# STM32G534 register map
File version: 2.0.0
CPU: CM33 r0p4, little endian, MPU, FPU, 4 interrupt priority bits
Registers are 32-bit, read-write, reset 0x0 unless marked. A register's access mark holds for its fields unless they carry their own. Offsets are from the block's base; [hi:lo] are bit positions; {n}, {i} and the like mark numbered series.

## FMAC1 — FMAC register block
Base 0x40023C00
Same registers: FMAC1_S 0x50023C00
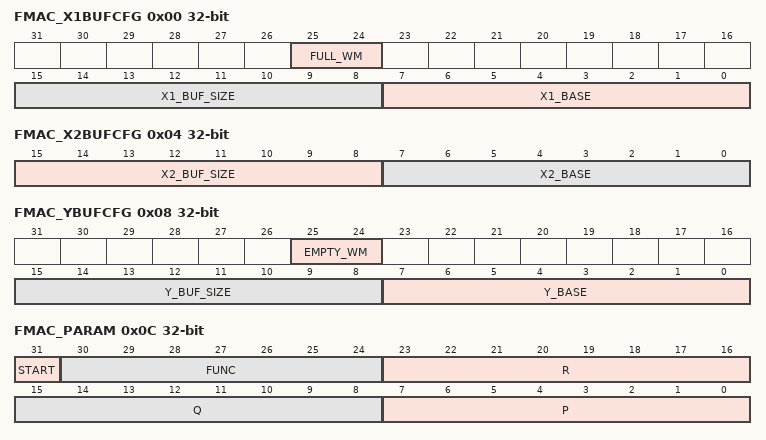
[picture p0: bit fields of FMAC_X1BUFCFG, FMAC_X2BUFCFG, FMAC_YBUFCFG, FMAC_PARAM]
0x00 FMAC_X1BUFCFG — FMAC X1 buffer configuration register
  [25:24] FULL_WM — Watermark for buffer full flag
    0=Threshold = 1; 1=Threshold = 2
  [15:8] X1_BUF_SIZE — Allocated size of X1 buffer in 16-bit words
  [7:0] X1_BASE — Base address of X1 buffer
0x04 FMAC_X2BUFCFG — FMAC X2 buffer configuration register
  [15:8] X2_BUF_SIZE — Size of X2 buffer in 16-bit words
  [7:0] X2_BASE — Base address of X2 buffer
0x08 FMAC_YBUFCFG — FMAC Y buffer configuration register
  [25:24] EMPTY_WM — Watermark for buffer empty flag
    0=Threshold = 1; 1=Threshold = 2
  [15:8] Y_BUF_SIZE — Size of Y buffer in 16-bit words
  [7:0] Y_BASE — Base address of Y buffer
0x0C FMAC_PARAM — FMAC parameter register
  [31] START — Enable execution
    0=Stop execution; 1=Start execution
  [30:24] FUNC — Function
    1=Load X1 buffer
  [23:16] R — Input parameter R.
  [15:8] Q — Input parameter Q.
  [7:0] P — Input parameter P.
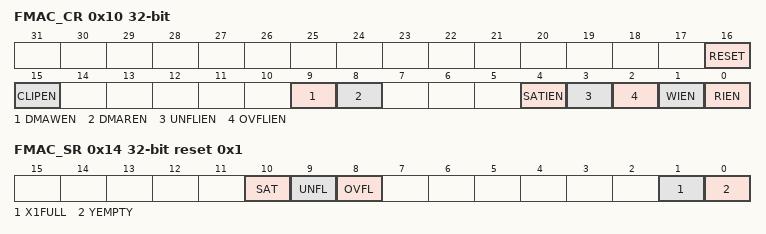
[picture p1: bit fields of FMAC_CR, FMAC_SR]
0x10 FMAC_CR — FMAC control register
  [16] RESET — Reset FMAC unit
    0=Reset inactive; 1=Reset active
  [15] CLIPEN — Enable clipping
    0=Clipping disabled; 1=Clipping enabled
  [9] DMAWEN — Enable DMA write channel requests
    0=Disable; 1=Enable
  [8] DMAREN — Enable DMA read channel requests
    0=Disable; 1=Enable
  [4] SATIEN — Enable saturation error interrupts
    0=Disabled; 1=Enabled
  [3] UNFLIEN — Enable underflow error interrupts
    0=Disabled; 1=Enabled
  [2] OVFLIEN — Enable overflow error interrupts
    0=Disabled; 1=Enabled
  [1] WIEN — Enable write interrupt
    0=Disabled; 1=Enabled
  [0] RIEN — Enable read interrupt
    0=Disabled; 1=Enabled
0x14 FMAC_SR ro reset 0x1 — FMAC status register
  [10] SAT — Saturation error flag
    0=No saturation detected; 1=Saturation detected
  [9] UNFL — Underflow error flag
    0=No underflow detected; 1=Underflow detected
  [8] OVFL — Overflow error flag
    0=No overflow detected; 1=Overflow detected
  [1] X1FULL — X1 buffer full flag
    0=X1 buffer not full; 1=X1 buffer full
  [0] YEMPTY — Y buffer empty flag
    0=Y buffer not empty; 1=Y buffer empty
0x18 FMAC_WDATA wo — FMAC write data register
  [15:0] WDATA — Write data
0x1C FMAC_RDATA ro — FMAC read data register
  [15:0] RDATA — Read data

## GTZC1_MPCBB2 — GTZC1_MPCBB2 register block
Base 0x40033000
Same registers: GTZC1_MPCBB2_S 0x50033000
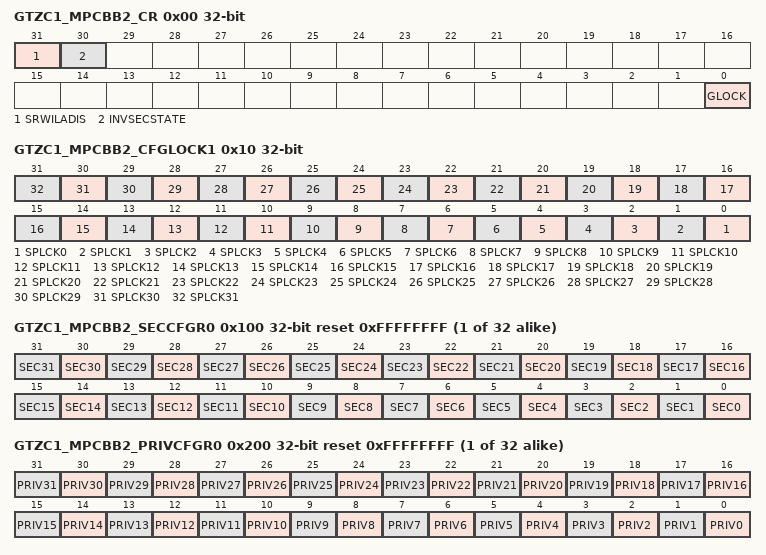
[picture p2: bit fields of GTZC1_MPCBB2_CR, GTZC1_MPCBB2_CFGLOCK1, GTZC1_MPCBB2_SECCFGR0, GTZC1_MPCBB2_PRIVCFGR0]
0x00 GTZC1_MPCBB2_CR — PLAYGTZC1 SRAM2 MPCBB control register
  [31] SRWILADIS — secure read/write illegal access disable
    0=enabled, secure read/write access not allowed on nonsecure SRAM block; 1=disabled, secure read/write access allowed on nonsecure SRAM block
  [30] INVSECSTATE — SRAMx clocks security state
    0=SRAMs clocks are secure if a secure area exists in the MPCBB; 1=SRAMs clocks are nonsecure even if a secure area exists in the MPCBB, and secure even if no secure block is set in the MPCBB
  [0] GLOCK — lock the control register of the MPCBB until next reset
    0=control register not locked; 1=control register locked
0x10 GTZC1_MPCBB2_CFGLOCK1 — GTZC1 SRAM2 MPCBB configuration lock register 1
  [all] fields
    0=GTZC1_MPCBBz_SECCFGRy and GTZC1_MPCBBz_PRIVCFGRy can be written; 1=Writes to GTZC1_MPCBBz_SECCFGRy and GTZC1_MPCBBz_PRIVCFGRy are ignored
  [n] SPLCK{n} (n=0..31) — Security/privilege configuration lock for super-block
{0x100+4i} GTZC1_MPCBB2_SECCFGR{i} reset 0xFFFFFFFF (i=0..31) — GTZC1 SRAM2 MPCBB security configuration for super-block {i} register
  [all] fields
    0=nonsecure access only to block y, belonging to super-block x; 1=Secure access only to block y, belonging to super-block x
  [n] SEC{n} (n=0..31) — Security configuration for block y
{0x200+4i} GTZC1_MPCBB2_PRIVCFGR{i} reset 0xFFFFFFFF (i=0..31) — GTZC1 SRAM2 MPCBB privileged configuration for super-block {i} register
  [all] fields
    0=Privileged and unprivileged access to block y, belonging to super-block x; 1=Only privileged access to block y, belonging to super-block x
  [n] PRIV{n} (n=0..31) — Privileged configuration for block y, belonging to super-block x (y = 31 to 0).
